# STM32WBA52 register map
File version: 0.1
CPU: CM33 r0p1, little endian, MPU, FPU, 4 interrupt priority bits
Registers are 32-bit, read-write, reset 0x0 unless marked. A register's access mark holds for its fields unless they carry their own. Offsets are from the block's base; [hi:lo] are bit positions; 'fields as' and 'values as' point back to an identical list.

## USART1 (part 1 of 2) — Universal synchronous asynchronous receiver transmitter
Base 0x40013800
Same registers: USART2 0x40004400, SEC_USART2 0x50004400, SEC_USART1 0x50013800
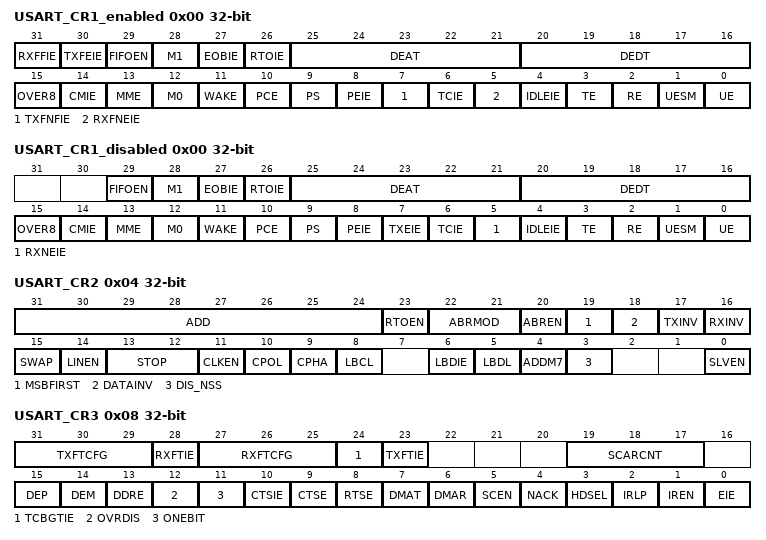
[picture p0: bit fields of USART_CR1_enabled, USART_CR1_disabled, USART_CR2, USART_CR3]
0x00 USART_CR1_enabled — USART control register 1 [alternate]
  [31] RXFFIE — RXFIFO Full interrupt enable This bit is set and cleared by software.
    0=Interrupt inhibited; 1=USART interrupt generated when RXFF=1 in the USART_ISR register
  [30] TXFEIE — TXFIFO empty interrupt enable This bit is set and cleared by software.
    0=Interrupt inhibited; 1=USART interrupt generated when TXFE=1 in the USART_ISR register
  [29] FIFOEN — FIFO mode enable This bit is set and cleared by software. This bitfield can only be written when the USART is disabled (UE=0). Note: FIFO mode can be used on standard UART communication, in SPI Master/Slave mode and in Smartcard modes only. It must not be enabled in IrDA and LIN modes.
    0=FIFO mode is disabled; 1=FIFO mode is enabled
  [28] M1 — Word length This bit must be used in conjunction with bit 12 (M0) to determine the word length. It is set or cleared by software. M[1:0] = 00: 1 start bit, 8 Data bits, n Stop bit M[1:0] = 01: 1 start bit, 9 Data bits, n Stop bit M[1:0] = 10: 1 start bit, 7 Data bits, n Stop bit This bit can only be written when the USART is disabled (UE=0). Note: In 7-bits data length mode, the Smartcard mode, LIN master mode and auto baud rate (0x7F and 0x55 frames detection) are not supported.
  [27] EOBIE — End of Block interrupt enable This bit is set and cleared by software. Note: If the USART does not support Smartcard mode, this bit is reserved and must be kept at reset value. Refer to Section 78.4: USART implementation on page 4565.
    0=Interrupt inhibited; 1=USART interrupt generated when the EOBF flag is set in the USART_ISR register
  [26] RTOIE — Receiver timeout interrupt enable This bit is set and cleared by software. Note: If the USART does not support the Receiver timeout feature, this bit is reserved and must be kept at reset value. Section�78.4: USART implementation on page�4565.
    0=Interrupt inhibited; 1=USART interrupt generated when the RTOF bit is set in the USART_ISR register
  [25:21] DEAT — Driver Enable assertion time This 5-bit value defines the time between the activation of the DE (Driver Enable) signal and the beginning of the start bit. It is expressed in sample time units (1/8 or 1/16 bit time, depending on the oversampling rate). This bitfield can only be written when the USART is disabled (UE=0). Note: If the Driver Enable feature is not supported, this bit is reserved and must be kept at reset value. Refer to Section 78.4: USART implementation on page 4565.
  [20:16] DEDT — Driver Enable deassertion time This 5-bit value defines the time between the end of the last stop bit, in a transmitted message, and the de-activation of the DE (Driver Enable) signal. It is expressed in sample time units (1/8 or 1/16 bit time, depending on the oversampling rate). If the USART_TDR register is written during the DEDT time, the new data is transmitted only when the DEDT and DEAT times have both elapsed. This bitfield can only be written when the USART is disabled (UE=0). Note: If the Driver Enable feature is not supported, this bit is reserved and must be kept at reset value. Refer to Section 78.4: USART implementation on page 4565.
  [15] OVER8 — Oversampling mode This bit can only be written when the USART is disabled (UE=0). Note: In LIN, IrDA and Smartcard modes, this bit must be kept cleared.
    0=Oversampling by 16; 1=Oversampling by 8
  [14] CMIE — Character match interrupt enable This bit is set and cleared by software.
    0=Interrupt inhibited; 1=USART interrupt generated when the CMF bit is set in the USART_ISR register
  [13] MME — Mute mode enable This bit enables the USART Mute mode function. When set, the USART can switch between active and Mute mode, as defined by the WAKE bit. It is set and cleared by software.
    0=Receiver in Active mode permanently; 1=Receiver can switch between Mute mode and Active mode
  [12] M0 — Word length This bit is used in conjunction with bit 28 (M1) to determine the word length. It is set or cleared by software (refer to bit 28 (M1)description). This bit can only be written when the USART is disabled (UE=0).
  [11] WAKE — Receiver wakeup method This bit determines the USART wakeup method from Mute mode. It is set or cleared by software. This bitfield can only be written when the USART is disabled (UE=0).
    0=Idle line; 1=Address mark
  [10] PCE — Parity control enable This bit selects the hardware parity control (generation and detection). When the parity control is enabled, the computed parity is inserted at the MSB position (9th bit if M=1; 8th bit if M=0) and the parity is checked on the received data. This bit is set and cleared by software. Once it is set, PCE is active after the current byte (in reception and in transmission). This bitfield can only be written when the USART is disabled (UE=0).
    0=Parity control disabled; 1=Parity control enabled
  [9] PS — Parity selection This bit selects the odd or even parity when the parity generation/detection is enabled (PCE bit set). It is set and cleared by software. The parity is selected after the current byte. This bitfield can only be written when the USART is disabled (UE=0).
    0=Even parity; 1=Odd parity
  [8] PEIE — PE interrupt enable This bit is set and cleared by software.
    0=Interrupt inhibited; 1=USART interrupt generated whenever PE=1 in the USART_ISR register
  [7] TXFNFIE — TXFIFO not full interrupt enable This bit is set and cleared by software.
    0=Interrupt inhibited; 1=USART interrupt generated whenever TXFNF =1 in the USART_ISR register
  [6] TCIE — Transmission complete interrupt enable This bit is set and cleared by software.
    0=Interrupt inhibited; 1=USART interrupt generated whenever TC=1 in the USART_ISR register
  [5] RXFNEIE — RXFIFO not empty interrupt enable This bit is set and cleared by software.
    0=Interrupt inhibited; 1=USART interrupt generated whenever ORE=1 or RXFNE=1 in the USART_ISR register
  [4] IDLEIE — IDLE interrupt enable This bit is set and cleared by software.
    0=Interrupt inhibited; 1=USART interrupt generated whenever IDLE=1 in the USART_ISR register
  [3] TE — Transmitter enable This bit enables the transmitter. When the Autonomous mode is not used, TE bit is set and cleared by software. When the Autonomous mode is used, TE bit becomes a status bit, which is set and cleared by hardware. Note: During transmission, a low pulse on the TE bit (0 followed by 1) sends a preamble (idle line) after the current word, except in Smartcard mode. In order to generate an idle character, the TE must not be immediately written to 1. To ensure the required duration, the software can poll the TEACK bit in the USART_ISR register. Note: In Smartcard mode, when TE is set, there is a 1 bit-time delay before the transmission starts.
    0=Transmitter is disabled; 1=Transmitter is enabled
  [2] RE — Receiver enable This bit enables the receiver. It is set and cleared by software.
    0=Receiver is disabled; 1=Receiver is enabled and begins searching for a start bit
  [1] UESM — USART enable in low-power mode When this bit is cleared, the USART cannot request its kernel clock and is not functional in low-power mode. When this bit is set, the USART can wake up the MCU from low-power mode. This bit is set and cleared by software. Note: The UESM bit must be set at the initialization phase. Note: If the USART does not support the wakeup from low-power mode, this bit is reserved and must be kept at reset value. Refer to Section�78.4: USART implementation on page�4565.
    0=USART not functional in low-power mode; 1=USART functional in low-power mode
  [0] UE — USART enable When this bit is cleared, the USART prescalers and outputs are stopped immediately, and all current operations are discarded. The USART configuration is kept, but all the USART_ISR status flags are reset. This bit is set and cleared by software. Note: To enter low-power mode without generating errors on the line, the TE bit must be previously reset and the software must wait for the TC bit in the USART_ISR to be set before resetting the UE bit. Note: The DMA requests are also reset when UE = 0 so the DMA channel must be disabled before resetting the UE bit. Note: In Smartcard mode, (SCEN = 1), the CK is always available when CLKEN = 1, regardless of the UE bit value.
    0=USART prescaler and outputs disabled, low-power mode; 1=USART enabled
0x00 USART_CR1_disabled (alternate view of USART_CR1_enabled) — USART control register 1 [alternate]
  [29] FIFOEN — FIFO mode enable This bit is set and cleared by software. This bitfield can only be written when the USART is disabled (UE=0). Note: FIFO mode can be used on standard UART communication, in SPI Master/Slave mode and in Smartcard modes only. It must not be enabled in IrDA and LIN modes.
    0=FIFO mode is disabled; 1=FIFO mode is enabled
  [28] M1 — Word length This bit must be used in conjunction with bit 12 (M0) to determine the word length. It is set or cleared by software. M[1:0] = 00: 1 start bit, 8 Data bits, n Stop bit M[1:0] = 01: 1 start bit, 9 Data bits, n Stop bit M[1:0] = 10: 1 start bit, 7 Data bits, n Stop bit This bit can only be written when the USART is disabled (UE=0). Note: In 7-bits data length mode, the Smartcard mode, LIN master mode and auto baud rate (0x7F and 0x55 frames detection) are not supported.
  [27] EOBIE — End of Block interrupt enable This bit is set and cleared by software. Note: If the USART does not support Smartcard mode, this bit is reserved and must be kept at reset value. Refer to Section 78.4: USART implementation on page 4565.
    values as USART_CR1_enabled.EOBIE
  [26] RTOIE — Receiver timeout interrupt enable This bit is set and cleared by software. Note: If the USART does not support the Receiver timeout feature, this bit is reserved and must be kept at reset value. Section�78.4: USART implementation on page�4565.
    values as USART_CR1_enabled.RTOIE
  [25:21] DEAT — Driver Enable assertion time This 5-bit value defines the time between the activation of the DE (Driver Enable) signal and the beginning of the start bit. It is expressed in sample time units (1/8 or 1/16 bit time, depending on the oversampling rate). This bitfield can only be written when the USART is disabled (UE=0). Note: If the Driver Enable feature is not supported, this bit is reserved and must be kept at reset value. Refer to Section 78.4: USART implementation on page 4565.
  [20:16] DEDT — Driver Enable deassertion time This 5-bit value defines the time between the end of the last stop bit, in a transmitted message, and the de-activation of the DE (Driver Enable) signal. It is expressed in sample time units (1/8 or 1/16 bit time, depending on the oversampling rate). If the USART_TDR register is written during the DEDT time, the new data is transmitted only when the DEDT and DEAT times have both elapsed. This bitfield can only be written when the USART is disabled (UE=0). Note: If the Driver Enable feature is not supported, this bit is reserved and must be kept at reset value. Refer to Section 78.4: USART implementation on page 4565.
  [15] OVER8 — Oversampling mode This bit can only be written when the USART is disabled (UE=0). Note: In LIN, IrDA and Smartcard modes, this bit must be kept cleared.
    0=Oversampling by 16; 1=Oversampling by 8
  [14] CMIE — Character match interrupt enable This bit is set and cleared by software.
    values as USART_CR1_enabled.CMIE
  [13] MME — Mute mode enable This bit enables the USART Mute mode function. When set, the USART can switch between active and Mute mode, as defined by the WAKE bit. It is set and cleared by software.
    values as USART_CR1_enabled.MME
  [12] M0 — Word length This bit is used in conjunction with bit 28 (M1) to determine the word length. It is set or cleared by software (refer to bit 28 (M1)description). This bit can only be written when the USART is disabled (UE=0).
  [11] WAKE — Receiver wakeup method This bit determines the USART wakeup method from Mute mode. It is set or cleared by software. This bitfield can only be written when the USART is disabled (UE=0).
    0=Idle line; 1=Address mark
  [10] PCE — Parity control enable This bit selects the hardware parity control (generation and detection). When the parity control is enabled, the computed parity is inserted at the MSB position (9th bit if M=1; 8th bit if M=0) and the parity is checked on the received data. This bit is set and cleared by software. Once it is set, PCE is active after the current byte (in reception and in transmission). This bitfield can only be written when the USART is disabled (UE=0).
    0=Parity control disabled; 1=Parity control enabled
  [9] PS — Parity selection This bit selects the odd or even parity when the parity generation/detection is enabled (PCE bit set). It is set and cleared by software. The parity is selected after the current byte. This bitfield can only be written when the USART is disabled (UE=0).
    0=Even parity; 1=Odd parity
  [8] PEIE — PE interrupt enable This bit is set and cleared by software.
    values as USART_CR1_enabled.PEIE
  [7] TXEIE — Transmit data register empty This bit is set and cleared by software.
    0=Interrupt inhibited; 1=USART interrupt generated whenever TXE =1 in the USART_ISR register
  [6] TCIE — Transmission complete interrupt enable This bit is set and cleared by software.
    values as USART_CR1_enabled.TCIE
  [5] RXNEIE — Receive data register not empty This bit is set and cleared by software.
    0=Interrupt inhibited; 1=USART interrupt generated whenever ORE=1 or RXNE=1 in the USART_ISR register
  [4] IDLEIE — IDLE interrupt enable This bit is set and cleared by software.
    values as USART_CR1_enabled.IDLEIE
  [3] TE — Transmitter enable This bit enables the transmitter. When the Autonomous mode is not used, TE bit is set and cleared by software. When the Autonomous mode is used, TE bit becomes a status bit, which is set and cleared by hardware. Note: During transmission, a low pulse on the TE bit (0 followed by 1) sends a preamble (idle line) after the current word, except in Smartcard mode. In order to generate an idle character, the TE must not be immediately written to 1. To ensure the required duration, the software can poll the TEACK bit in the USART_ISR register. Note: In Smartcard mode, when TE is set, there is a 1 bit-time delay before the transmission starts.
    0=Transmitter is disabled; 1=Transmitter is enabled
  [2] RE — Receiver enable This bit enables the receiver. It is set and cleared by software.
    values as USART_CR1_enabled.RE
  [1] UESM — USART enable in low-power mode When this bit is cleared, the USART cannot request its kernel clock and is not functional in low-power mode. When this bit is set, the USART can wake up the MCU from low-power mode. This bit is set and cleared by software. Note: The UESM bit must be set at the initialization phase. Note: If the USART does not support the wakeup from low-power mode, this bit is reserved and must be kept at reset value. Refer to Section�78.4: USART implementation on page�4565.
    values as USART_CR1_enabled.UESM
  [0] UE — USART enable When this bit is cleared, the USART prescalers and outputs are stopped immediately, and all current operations are discarded. The USART configuration is kept, but all the USART_ISR status flags are reset. This bit is set and cleared by software. Note: To enter low-power mode without generating errors on the line, the TE bit must be previously reset and the software must wait for the TC bit in the USART_ISR to be set before resetting the UE bit. Note: The DMA requests are also reset when UE = 0 so the DMA channel must be disabled before resetting the UE bit. Note: In Smartcard mode, (SCEN = 1), the CK is always available when CLKEN = 1, regardless of the UE bit value.
    values as USART_CR1_enabled.UE
0x04 USART_CR2 — USART control register 2
  [31:24] ADD — Address of the USART node These bits give the address of the USART node in Mute mode or a character code to be recognized in low-power or Run mode: In Mute mode: they are used in multiprocessor communication to wakeup from Mute mode with 4-bit/7-bit address mark detection. The MSB of the character sent by the transmitter should be equal to 1. In 4-bit address mark detection, only ADD[3:0] bits are used. In low-power mode: they are used for wake up from low-power mode on character match. When a character, received during low-power mode, corresponds to the character programmed through ADD[7:0] bitfield, the CMF flag is set and wakes up the device from low-power mode if the corresponding interrupt is enabled by setting CMIE bit. In Run mode with Mute mode inactive (for example, end-of-block detection in ModBus protocol): the whole received character (8 bits) is compared to ADD[7:0] value and CMF flag is set on match. An interrupt is generated if the CMIE bit is set. These bits can only be written when the reception is disabled (RE�=�0) or when the USART is disabled (UE�=�0).
  [23] RTOEN — Receiver timeout enable This bit is set and cleared by software. When this feature is enabled, the RTOF flag in the USART_ISR register is set if the RX line is idle (no reception) for the duration programmed in the RTOR (receiver timeout register). Note: If the USART does not support the Receiver timeout feature, this bit is reserved and must be kept at reset value. Refer to Section�78.4: USART implementation on page�4565.
    0=Receiver timeout feature disabled; 1=Receiver timeout feature enabled
  [22:21] ABRMOD — Auto baud rate mode These bits are set and cleared by software. This bitfield can only be written when ABREN = 0 or the USART is disabled (UE=0). Note: If DATAINV=1 and/or MSBFIRST=1 the patterns must be the same on the line, for example 0xAA for MSBFIRST) Note: If the USART does not support the auto baud rate feature, this bit is reserved and must be kept at reset value. Refer to Section�78.4: USART implementation on page�4565.
    0=Measurement of the start bit is used to detect the baud rate; 1=Falling edge to falling edge measurement (the received frame must start with a single bit = 1 -> Frame = Start10xxxxxx); 2=0x7F frame detection; 3=0x55 frame detection
  [20] ABREN — Auto baud rate enable This bit is set and cleared by software. Note: If the USART does not support the auto baud rate feature, this bit is reserved and must be kept at reset value. Refer to Section�78.4: USART implementation on page�4565.
    0=Auto baud rate detection is disabled; 1=Auto baud rate detection is enabled
  [19] MSBFIRST — Most significant bit first This bit is set and cleared by software. This bitfield can only be written when the USART is disabled (UE=0).
    0=data is transmitted/received with data bit 0 first, following the start bit; 1=data is transmitted/received with the MSB (bit 7/8) first, following the start bit
  [18] DATAINV — Binary data inversion This bit is set and cleared by software. This bitfield can only be written when the USART is disabled (UE=0).
    0=Logical data from the data register are send/received in positive/direct logic. (1=H, 0=L); 1=Logical data from the data register are send/received in negative/inverse logic. (1=L, 0=H). The parity bit is also inverted.
  [17] TXINV — TX pin active level inversion This bit is set and cleared by software. This enables the use of an external inverter on the TX line. This bitfield can only be written when the USART is disabled (UE=0).
    0=TX pin signal works using the standard logic levels (V<sub>DD</sub> =1/idle, Gnd=0/mark); 1=TX pin signal values are inverted. ((V<sub>DD</sub> =0/mark, Gnd=1/idle).
  [16] RXINV — RX pin active level inversion This bit is set and cleared by software. This enables the use of an external inverter on the RX line. This bitfield can only be written when the USART is disabled (UE=0).
    0=RX pin signal works using the standard logic levels (V<sub>DD</sub> =1/idle, Gnd=0/mark); 1=RX pin signal values are inverted. ((V<sub>DD</sub> =0/mark, Gnd=1/idle).
  [15] SWAP — Swap TX/RX pins This bit is set and cleared by software. This bitfield can only be written when the USART is disabled (UE=0).
    0=TX/RX pins are used as defined in standard pinout; 1=The TX and RX pins functions are swapped. This enables to work in the case of a cross-wired connection to another UART.
  [14] LINEN — LIN mode enable This bit is set and cleared by software. The LIN mode enables the capability to send LIN synchronous breaks (13 low bits) using the SBKRQ bit in the USART_CR1 register, and to detect LIN Sync breaks. This bitfield can only be written when the USART is disabled (UE=0). Note: If the USART does not support LIN mode, this bit is reserved and must be kept at reset value. Refer to Section�78.4: USART implementation on page�4565.
    0=LIN mode disabled; 1=LIN mode enabled
  [13:12] STOP — stop bits These bits are used for programming the stop bits. This bitfield can only be written when the USART is disabled (UE=0).
    0=1 stop bit; 1=0.5 stop bit; 2=2 stop bits; 3=1.5 stop bits
  [11] CLKEN — Clock enable This bit enables the user to enable the CK pin. This bit can only be written when the USART is disabled (UE=0). Note: If neither Synchronous mode nor Smartcard mode is supported, this bit is reserved and must be kept at reset value. Refer to Section�78.4: USART implementation on page�4565. In Smartcard mode, in order to provide correctly the CK clock to the smartcard, the steps below must be respected: UE = 0 SCEN = 1 GTPR configuration CLKEN= 1 Note: UE = 1
    0=CK pin disabled; 1=CK pin enabled
  [10] CPOL — Clock polarity This bit enables the user to select the polarity of the clock output on the CK pin in Synchronous mode. It works in conjunction with the CPHA bit to produce the desired clock/data relationship This bit can only be written when the USART is disabled (UE=0). Note: If Synchronous mode is not supported, this bit is reserved and must be kept at reset value. Refer to Section�78.4: USART implementation on page�4565.
    0=Steady low value on CK pin outside transmission window; 1=Steady high value on CK pin outside transmission window
  [9] CPHA — Clock phase This bit is used to select the phase of the clock output on the CK pin in Synchronous mode. It works in conjunction with the CPOL bit to produce the desired clock/data relationship (see Figure�933 and Figure�934) This bit can only be written when the USART is disabled (UE=0). Note: If Synchronous mode is not supported, this bit is reserved and must be kept at reset value. Refer to Section�78.4: USART implementation on page�4565.
    0=The first clock transition is the first data capture edge; 1=The second clock transition is the first data capture edge
  [8] LBCL — Last bit clock pulse This bit is used to select whether the clock pulse associated with the last data bit transmitted (MSB) has to be output on the CK pin in Synchronous mode. The last bit is the 7th or 8th or 9th data bit transmitted depending on the 7 or 8 or 9 bit format selected by the M bit in the USART_CR1 register. This bit can only be written when the USART is disabled (UE=0). Note: If Synchronous mode is not supported, this bit is reserved and must be kept at reset value. Refer to Section�78.4: USART implementation on page�4565.
    0=The clock pulse of the last data bit is not output to the CK pin; 1=The clock pulse of the last data bit is output to the CK pin
  [6] LBDIE — LIN break detection interrupt enable Break interrupt mask (break detection using break delimiter). Note: If LIN mode is not supported, this bit is reserved and must be kept at reset value. Refer to Section�78.4: USART implementation on page�4565.
    0=Interrupt is inhibited; 1=An interrupt is generated whenever LBDF=1 in the USART_ISR register
  [5] LBDL — LIN break detection length This bit is for selection between 11 bit or 10 bit break detection. This bit can only be written when the USART is disabled (UE=0). Note: If LIN mode is not supported, this bit is reserved and must be kept at reset value. Refer to Section�78.4: USART implementation on page�4565.
    0=10-bit break detection; 1=11-bit break detection
  [4] ADDM7 — 7-bit Address Detection/4-bit Address Detection This bit is for selection between 4-bit address detection or 7-bit address detection. This bit can only be written when the USART is disabled (UE=0) Note: In 7-bit and 9-bit data modes, the address detection is done on 6-bit and 8-bit address (ADD[5:0] and ADD[7:0]) respectively.
    0=4-bit address detection; 1=7-bit address detection (in 8-bit data mode)
  [3] DIS_NSS — When the DIS_NSS bit is set, the NSS pin input is ignored. Note: When SPI slave mode is not supported, this bit is reserved and must be kept at reset value. Refer to Section�78.4: USART implementation on page�4565.
    0=SPI slave selection depends on NSS input pin; 1=SPI slave is always selected and NSS input pin is ignored
  [0] SLVEN — Synchronous Slave mode enable When the SLVEN bit is set, the Synchronous slave mode is enabled. Note: When SPI slave mode is not supported, this bit is reserved and must be kept at reset value. Refer to Section�78.4: USART implementation on page�4565.
    0=Slave mode disabled; 1=Slave mode enabled
0x08 USART_CR3 — USART control register 3
  [31:29] TXFTCFG — TXFIFO threshold configuration Remaining combinations: Reserved
    0=TXFIFO reaches 1/8 of its depth; 1=TXFIFO reaches 1/4 of its depth; 2=TXFIFO reaches 1/2 of its depth; 3=TXFIFO reaches 3/4 of its depth; 4=TXFIFO reaches 7/8 of its depth; 5=TXFIFO becomes empty
  [28] RXFTIE — RXFIFO threshold interrupt enable This bit is set and cleared by software.
    0=Interrupt inhibited; 1=USART interrupt generated when Receive FIFO reaches the threshold programmed in RXFTCFG
  [27:25] RXFTCFG — Receive FIFO threshold configuration Remaining combinations: Reserved
    0=Receive FIFO reaches 1/8 of its depth; 1=Receive FIFO reaches 1/4 of its depth; 2=Receive FIFO reaches 1/2 of its depth; 3=Receive FIFO reaches 3/4 of its depth; 4=Receive FIFO reaches 7/8 of its depth; 5=Receive FIFO becomes full
  [24] TCBGTIE — Transmission Complete before guard time, interrupt enable This bit is set and cleared by software. Note: If the USART does not support the Smartcard mode, this bit is reserved and must be kept at reset value. Refer to Section�78.4: USART implementation on page�4565.
    0=Interrupt inhibited; 1=USART interrupt generated whenever TCBGT=1 in the USART_ISR register
  [23] TXFTIE — TXFIFO threshold interrupt enable This bit is set and cleared by software.
    0=Interrupt inhibited; 1=USART interrupt generated when TXFIFO reaches the threshold programmed in TXFTCFG
  [19:17] SCARCNT — Smartcard auto-retry count This bitfield specifies the number of retries for transmission and reception in Smartcard mode. In Transmission mode, it specifies the number of automatic retransmission retries, before generating a transmission error (FE bit set). In Reception mode, it specifies the number or erroneous reception trials, before generating a reception error (RXNE/RXFNE and PE bits set). This bitfield must be programmed only when the USART is disabled (UE=0). When the USART is enabled (UE=1), this bitfield may only be written to 0x0, in order to stop retransmission. 0x1 to 0x7: number of automatic retransmission attempts (before signaling error) Note: If Smartcard mode is not supported, this bit is reserved and must be kept at reset value. Refer to Section�78.4: USART implementation on page�4565.
    0=retransmission disabled - No automatic retransmission in Transmission mode
  [15] DEP — Driver enable polarity selection This bit can only be written when the USART is disabled (UE=0). Note: If the Driver Enable feature is not supported, this bit is reserved and must be kept at reset value. Refer to Section 78.4: USART implementation on page 4565.
    0=DE signal is active high; 1=DE signal is active low
  [14] DEM — Driver enable mode This bit enables the user to activate the external transceiver control, through the DE signal. This bit can only be written when the USART is disabled (UE=0). Note: If the Driver Enable feature is not supported, this bit is reserved and must be kept at reset value. Section 78.4: USART implementation on page 4565.
    0=DE function is disabled; 1=DE function is enabled. The DE signal is output on the RTS pin.
  [13] DDRE — DMA Disable on Reception Error This bit can only be written when the USART is disabled (UE=0). Note: The reception errors are: parity error, framing error or noise error.
    0=DMA is not disabled in case of reception error. The corresponding error flag is set but RXNE is kept 0 preventing from overrun. As a consequence, the DMA request is not asserted, so the erroneous data is not transferred (no DMA request), but next correct received data is transferred. (used for Smartcard mode); 1=DMA is disabled following a reception error. The corresponding error flag is set, as well as RXNE. The DMA request is masked until the error flag is cleared. This means that the software must first disable the DMA request (DMAR = 0) or clear RXNE(RXFNE is case FIFO mode is enabled) before clearing the error flag.
  [12] OVRDIS — Overrun Disable This bit is used to disable the receive overrun detection. the ORE flag is not set and the new received data overwrites the previous content of the USART_RDR register. When FIFO mode is enabled, the RXFIFO is bypassed and data are written directly in USART_RDR register. Even when FIFO management is enabled, the RXNE flag is to be used. This bit can only be written when the USART is disabled (UE=0). Note: This control bit enables checking the communication flow w/o reading the data
    0=Overrun Error Flag, ORE, is set when received data is not read before receiving new data; 1=Overrun functionality is disabled. If new data is received while the RXNE flag is still set
  [11] ONEBIT — One sample bit method enable This bit enables the user to select the sample method. When the one sample bit method is selected the noise detection flag (NE) is disabled. This bit can only be written when the USART is disabled (UE=0).
    0=Three sample bit method; 1=One sample bit method
  [10] CTSIE — CTS interrupt enable Note: If the hardware flow control feature is not supported, this bit is reserved and must be kept at reset value. Refer to Section�78.4: USART implementation on page�4565.
    0=Interrupt is inhibited; 1=An interrupt is generated whenever CTSIF=1 in the USART_ISR register
  [9] CTSE — CTS enable This bit can only be written when the USART is disabled (UE=0) Note: If the hardware flow control feature is not supported, this bit is reserved and must be kept at reset value. Refer to Section�78.4: USART implementation on page�4565.
    0=CTS hardware flow control disabled; 1=CTS mode enabled, data is only transmitted when the CTS input is deasserted (tied to 0). If the CTS input is asserted while data is being transmitted, then the transmission is completed before stopping.If data is written into the data register while CTS is asserted, the transmission is postponed until CTS is deasserted.
  [8] RTSE — RTS enable This bit can only be written when the USART is disabled (UE=0). Note: If the hardware flow control feature is not supported, this bit is reserved and must be kept at reset value. Refer to Section�78.4: USART implementation on page�4565.
    0=RTS hardware flow control disabled; 1=RTS output enabled, data is only requested when there is space in the receive buffer. The transmission of data is expected to cease after the current character has been transmitted. The RTS output is deasserted (pulled to 0) when data can be received.
  [7] DMAT — DMA enable transmitter This bit is set/reset by software
    1=DMA mode is enabled for transmission; 0=DMA mode is disabled for transmission
  [6] DMAR — DMA enable receiver This bit is set/reset by software
    1=DMA mode is enabled for reception; 0=DMA mode is disabled for reception
  [5] SCEN — Smartcard mode enable This bit is used for enabling Smartcard mode. This bitfield can only be written when the USART is disabled (UE=0). Note: If the USART does not support Smartcard mode, this bit is reserved and must be kept at reset value. Refer to Section�78.4: USART implementation on page�4565.
    0=Smartcard mode disabled; 1=Smartcard mode enabled
  [4] NACK — Smartcard NACK enable This bitfield can only be written when the USART is disabled (UE=0). Note: If the USART does not support Smartcard mode, this bit is reserved and must be kept at reset value. Refer to Section�78.4: USART implementation on page�4565.
    0=NACK transmission in case of parity error is disabled; 1=NACK transmission during parity error is enabled
  [3] HDSEL — Half-duplex selection Selection of Single-wire Half-duplex mode This bit can only be written when the USART is disabled (UE=0).
    0=Half-duplex mode is not selected; 1=Half-duplex mode is selected
  [2] IRLP — IrDA low-power This bit is used for selecting between normal and low-power IrDA modes This bit can only be written when the USART is disabled (UE=0). Note: If IrDA mode is not supported, this bit is reserved and must be kept at reset value. Refer to Section�78.4: USART implementation on page�4565.
    0=Normal mode; 1=Low-power mode
  [1] IREN — IrDA mode enable This bit is set and cleared by software. This bit can only be written when the USART is disabled (UE=0). Note: If IrDA mode is not supported, this bit is reserved and must be kept at reset value. Refer to Section�78.4: USART implementation on page�4565.
    0=IrDA disabled; 1=IrDA enabled
  [0] EIE — Error interrupt enable Error Interrupt Enable Bit is required to enable interrupt generation in case of a framing error, overrun error noise flag or SPI slave underrun error (FE=1 or ORE=1 or NE=1or UDR = 1 in the USART_ISR register).
    0=Interrupt inhibited; 1=interrupt generated when FE=1 or ORE=1 or NE=1 or UDR = 1 (in SPI slave mode) in the USART_ISR register
0x0C USART_BRR — USART baud rate register
  [15:0] BRR — USART baud rate BRR[15:4] BRR[15:4] correspond to USARTDIV[15:4] BRR[3:0] When OVER8 = 0, BRR[3:0] = USARTDIV[3:0]. When OVER8 = 1: BRR[2:0] = USARTDIV[3:0] shifted 1 bit to the right. BRR[3] must be kept cleared.
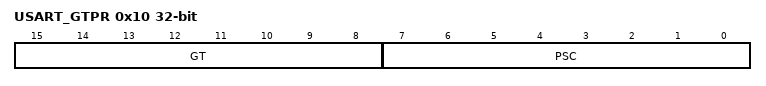
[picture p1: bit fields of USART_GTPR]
0x10 USART_GTPR — USART guard time and prescaler register
  [15:8] GT — Guard time value This bitfield is used to program the Guard time value in terms of number of baud clock periods. This is used in Smartcard mode. The Transmission Complete flag is set after this guard time value. This bitfield can only be written when the USART is disabled (UE=0). Note: If Smartcard mode is not supported, this bit is reserved and must be kept at reset value. Refer to Section�78.4: USART implementation on page�4565.
  [7:0] PSC — Prescaler value PSC[7:0] = IrDA Normal and Low-power baud rate This bitfield is used for programming the prescaler for dividing the USART source clock to achieve the low-power frequency: The source clock is divided by the value given in the register (8 significant bits): ... PSC[4:0]: Prescaler value This bitfield is used for programming the prescaler for dividing the USART source clock to provide the Smartcard clock. The value given in the register (5 significant bits) is multiplied by 2 to give the division factor of the source clock frequency: ... This bitfield can only be written when the USART is disabled (UE=0). Note: Bits [7:5] must be kept cleared if Smartcard mode is used. Note: This bitfield is reserved and forced by hardware to 0 when the Smartcard and IrDA modes are not supported. Refer to Section�78.4: USART implementation on page�4565.
    0=B_0x0_IRDA_LOW_POWER_AND_NORMAL_IRDA_MODE (Reserved - do not program this value); 1=B_0x1_IRDA_LOW_POWER_AND_NORMAL_IRDA_MODE (divides the source clock by 1); 2=B_0x2_IRDA_LOW_POWER_AND_NORMAL_IRDA_MODE (divides the source clock by 2); 0=B_0x0_SMARTCARD_MODE (Reserved - do not program this value); 1=B_0x1_SMARTCARD_MODE (divides the source clock by 2); 2=B_0x2_SMARTCARD_MODE (divides the source clock by 4); 3=B_0x3_SMARTCARD_MODE (divides the source clock by 6)
